VERSION "0.5"

NS_ :

BS_:

BU_: CM5 LEG_L1 LEG_L2 LEG_L3 LEG_R1 LEG_R2 LEG_R3 POWER

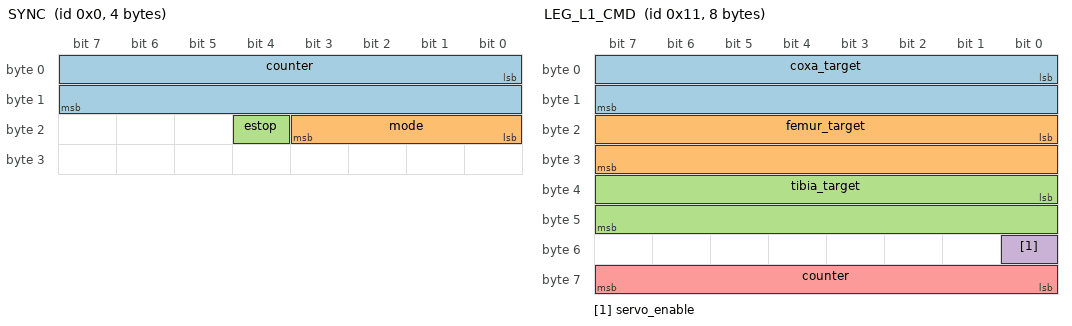
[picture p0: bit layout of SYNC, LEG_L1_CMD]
BO_ 0 SYNC: 4 CM5
 SG_ counter : 0|16@1+ (1,0) [0|65535] "" LEG_L1,LEG_L2,LEG_L3,LEG_R1,LEG_R2,LEG_R3,POWER
 SG_ mode : 16|4@1+ (1,0) [0|15] "" LEG_L1,LEG_L2,LEG_L3,LEG_R1,LEG_R2,LEG_R3,POWER
 SG_ estop : 20|1@1+ (1,0) [0|1] "" LEG_L1,LEG_L2,LEG_L3,LEG_R1,LEG_R2,LEG_R3,POWER

BO_ 17 LEG_L1_CMD: 8 CM5
 SG_ coxa_target : 0|16@1- (0.01,0) [-180|180] "deg" LEG_L1
 SG_ femur_target : 16|16@1- (0.01,0) [-180|180] "deg" LEG_L1
 SG_ tibia_target : 32|16@1- (0.01,0) [-180|180] "deg" LEG_L1
 SG_ servo_enable : 48|1@1+ (1,0) [0|1] "" LEG_L1
 SG_ counter : 56|8@1+ (1,0) [0|255] "" LEG_L1

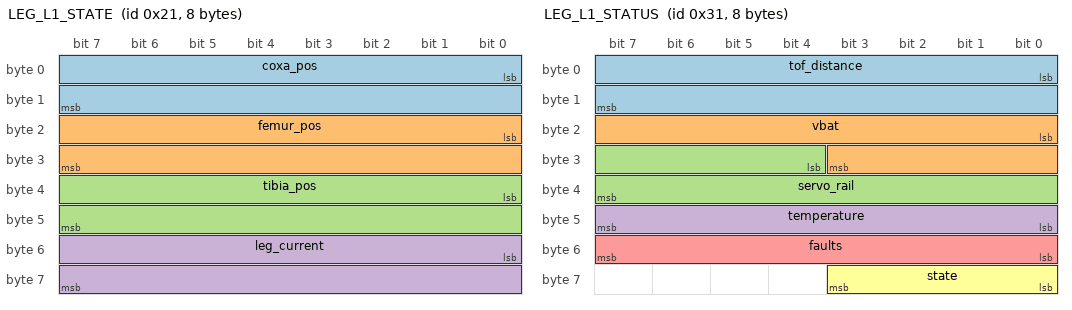
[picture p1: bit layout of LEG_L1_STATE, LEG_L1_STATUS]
BO_ 33 LEG_L1_STATE: 8 LEG_L1
 SG_ coxa_pos : 0|16@1- (0.01,0) [-180|180] "deg" CM5
 SG_ femur_pos : 16|16@1- (0.01,0) [-180|180] "deg" CM5
 SG_ tibia_pos : 32|16@1- (0.01,0) [-180|180] "deg" CM5
 SG_ leg_current : 48|16@1+ (1,0) [0|65535] "mA" CM5

BO_ 49 LEG_L1_STATUS: 8 LEG_L1
 SG_ tof_distance : 0|16@1+ (1,0) [0|65535] "mm" CM5
 SG_ vbat : 16|12@1+ (10,0) [0|40950] "mV" CM5
 SG_ servo_rail : 28|12@1+ (10,0) [0|40950] "mV" CM5
 SG_ temperature : 40|8@1- (1,0) [-128|127] "degC" CM5
 SG_ faults : 48|8@1+ (1,0) [0|255] "" CM5
 SG_ state : 56|4@1+ (1,0) [0|15] "" CM5

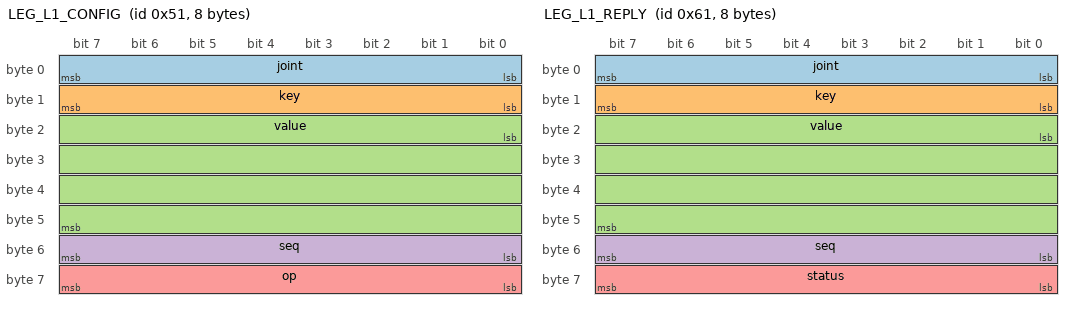
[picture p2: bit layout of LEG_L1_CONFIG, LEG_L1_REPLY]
BO_ 81 LEG_L1_CONFIG: 8 CM5
 SG_ joint : 0|8@1+ (1,0) [0|255] "" LEG_L1
 SG_ key : 8|8@1+ (1,0) [0|255] "" LEG_L1
 SG_ value : 16|32@1- (1,0) [-2147483648|2147483647] "" LEG_L1
 SG_ seq : 48|8@1+ (1,0) [0|255] "" LEG_L1
 SG_ op : 56|8@1+ (1,0) [0|255] "" LEG_L1

BO_ 97 LEG_L1_REPLY: 8 LEG_L1
 SG_ joint : 0|8@1+ (1,0) [0|255] "" CM5
 SG_ key : 8|8@1+ (1,0) [0|255] "" CM5
 SG_ value : 16|32@1- (1,0) [-2147483648|2147483647] "" CM5
 SG_ seq : 48|8@1+ (1,0) [0|255] "" CM5
 SG_ status : 56|8@1+ (1,0) [0|255] "" CM5

BO_ 113 BOOT_L1: 8 CM5
 SG_ op : 0|8@1+ (1,0) [0|255] "" LEG_L1
 SG_ payload : 8|56@1+ (1,0) [0|0] "" LEG_L1

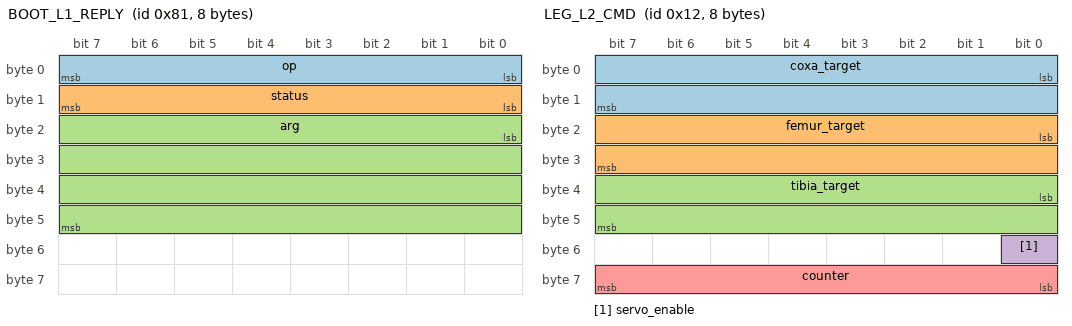
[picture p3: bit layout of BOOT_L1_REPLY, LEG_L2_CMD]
BO_ 129 BOOT_L1_REPLY: 8 LEG_L1
 SG_ op : 0|8@1+ (1,0) [0|255] "" CM5
 SG_ status : 8|8@1+ (1,0) [0|255] "" CM5
 SG_ arg : 16|32@1+ (1,0) [0|4294967295] "" CM5

BO_ 18 LEG_L2_CMD: 8 CM5
 SG_ coxa_target : 0|16@1- (0.01,0) [-180|180] "deg" LEG_L2
 SG_ femur_target : 16|16@1- (0.01,0) [-180|180] "deg" LEG_L2
 SG_ tibia_target : 32|16@1- (0.01,0) [-180|180] "deg" LEG_L2
 SG_ servo_enable : 48|1@1+ (1,0) [0|1] "" LEG_L2
 SG_ counter : 56|8@1+ (1,0) [0|255] "" LEG_L2

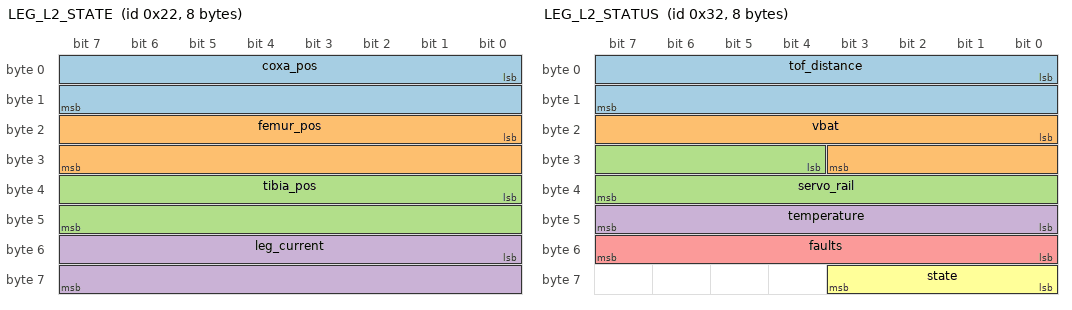
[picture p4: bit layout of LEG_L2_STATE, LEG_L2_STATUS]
BO_ 34 LEG_L2_STATE: 8 LEG_L2
 SG_ coxa_pos : 0|16@1- (0.01,0) [-180|180] "deg" CM5
 SG_ femur_pos : 16|16@1- (0.01,0) [-180|180] "deg" CM5
 SG_ tibia_pos : 32|16@1- (0.01,0) [-180|180] "deg" CM5
 SG_ leg_current : 48|16@1+ (1,0) [0|65535] "mA" CM5

BO_ 50 LEG_L2_STATUS: 8 LEG_L2
 SG_ tof_distance : 0|16@1+ (1,0) [0|65535] "mm" CM5
 SG_ vbat : 16|12@1+ (10,0) [0|40950] "mV" CM5
 SG_ servo_rail : 28|12@1+ (10,0) [0|40950] "mV" CM5
 SG_ temperature : 40|8@1- (1,0) [-128|127] "degC" CM5
 SG_ faults : 48|8@1+ (1,0) [0|255] "" CM5
 SG_ state : 56|4@1+ (1,0) [0|15] "" CM5

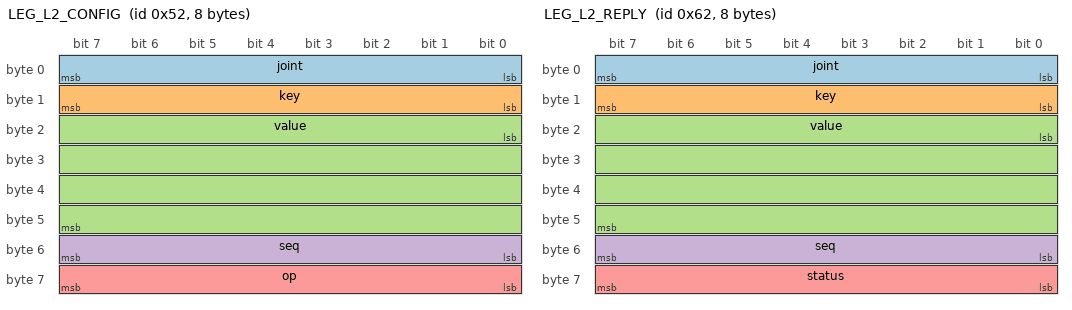
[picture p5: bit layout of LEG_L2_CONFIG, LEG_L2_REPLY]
BO_ 82 LEG_L2_CONFIG: 8 CM5
 SG_ joint : 0|8@1+ (1,0) [0|255] "" LEG_L2
 SG_ key : 8|8@1+ (1,0) [0|255] "" LEG_L2
 SG_ value : 16|32@1- (1,0) [-2147483648|2147483647] "" LEG_L2
 SG_ seq : 48|8@1+ (1,0) [0|255] "" LEG_L2
 SG_ op : 56|8@1+ (1,0) [0|255] "" LEG_L2

BO_ 98 LEG_L2_REPLY: 8 LEG_L2
 SG_ joint : 0|8@1+ (1,0) [0|255] "" CM5
 SG_ key : 8|8@1+ (1,0) [0|255] "" CM5
 SG_ value : 16|32@1- (1,0) [-2147483648|2147483647] "" CM5
 SG_ seq : 48|8@1+ (1,0) [0|255] "" CM5
 SG_ status : 56|8@1+ (1,0) [0|255] "" CM5

BO_ 114 BOOT_L2: 8 CM5
 SG_ op : 0|8@1+ (1,0) [0|255] "" LEG_L2
 SG_ payload : 8|56@1+ (1,0) [0|0] "" LEG_L2

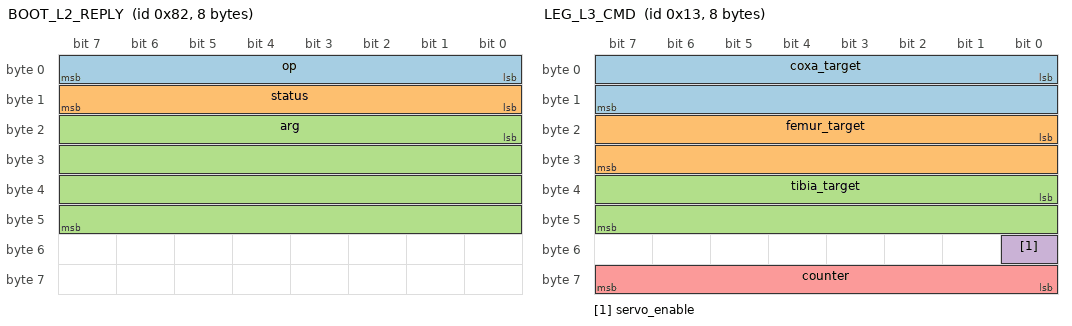
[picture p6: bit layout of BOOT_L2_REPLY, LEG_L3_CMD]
BO_ 130 BOOT_L2_REPLY: 8 LEG_L2
 SG_ op : 0|8@1+ (1,0) [0|255] "" CM5
 SG_ status : 8|8@1+ (1,0) [0|255] "" CM5
 SG_ arg : 16|32@1+ (1,0) [0|4294967295] "" CM5

BO_ 19 LEG_L3_CMD: 8 CM5
 SG_ coxa_target : 0|16@1- (0.01,0) [-180|180] "deg" LEG_L3
 SG_ femur_target : 16|16@1- (0.01,0) [-180|180] "deg" LEG_L3
 SG_ tibia_target : 32|16@1- (0.01,0) [-180|180] "deg" LEG_L3
 SG_ servo_enable : 48|1@1+ (1,0) [0|1] "" LEG_L3
 SG_ counter : 56|8@1+ (1,0) [0|255] "" LEG_L3

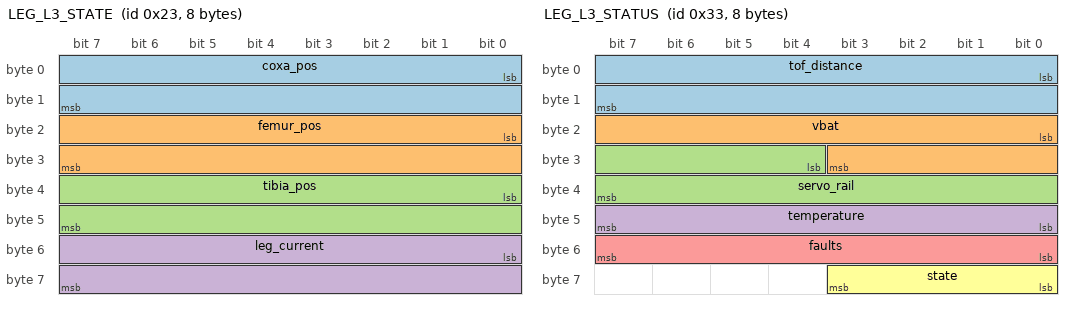
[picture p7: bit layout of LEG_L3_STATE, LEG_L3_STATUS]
BO_ 35 LEG_L3_STATE: 8 LEG_L3
 SG_ coxa_pos : 0|16@1- (0.01,0) [-180|180] "deg" CM5
 SG_ femur_pos : 16|16@1- (0.01,0) [-180|180] "deg" CM5
 SG_ tibia_pos : 32|16@1- (0.01,0) [-180|180] "deg" CM5
 SG_ leg_current : 48|16@1+ (1,0) [0|65535] "mA" CM5

BO_ 51 LEG_L3_STATUS: 8 LEG_L3
 SG_ tof_distance : 0|16@1+ (1,0) [0|65535] "mm" CM5
 SG_ vbat : 16|12@1+ (10,0) [0|40950] "mV" CM5
 SG_ servo_rail : 28|12@1+ (10,0) [0|40950] "mV" CM5
 SG_ temperature : 40|8@1- (1,0) [-128|127] "degC" CM5
 SG_ faults : 48|8@1+ (1,0) [0|255] "" CM5
 SG_ state : 56|4@1+ (1,0) [0|15] "" CM5

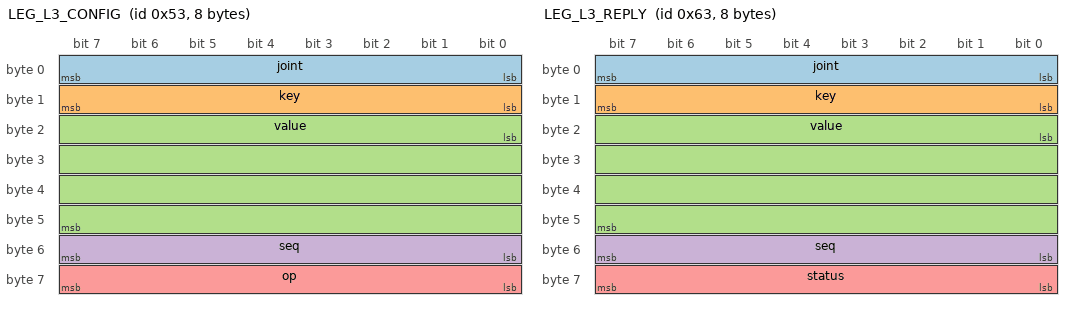
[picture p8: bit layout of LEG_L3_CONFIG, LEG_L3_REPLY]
BO_ 83 LEG_L3_CONFIG: 8 CM5
 SG_ joint : 0|8@1+ (1,0) [0|255] "" LEG_L3
 SG_ key : 8|8@1+ (1,0) [0|255] "" LEG_L3
 SG_ value : 16|32@1- (1,0) [-2147483648|2147483647] "" LEG_L3
 SG_ seq : 48|8@1+ (1,0) [0|255] "" LEG_L3
 SG_ op : 56|8@1+ (1,0) [0|255] "" LEG_L3

BO_ 99 LEG_L3_REPLY: 8 LEG_L3
 SG_ joint : 0|8@1+ (1,0) [0|255] "" CM5
 SG_ key : 8|8@1+ (1,0) [0|255] "" CM5
 SG_ value : 16|32@1- (1,0) [-2147483648|2147483647] "" CM5
 SG_ seq : 48|8@1+ (1,0) [0|255] "" CM5
 SG_ status : 56|8@1+ (1,0) [0|255] "" CM5

BO_ 115 BOOT_L3: 8 CM5
 SG_ op : 0|8@1+ (1,0) [0|255] "" LEG_L3
 SG_ payload : 8|56@1+ (1,0) [0|0] "" LEG_L3

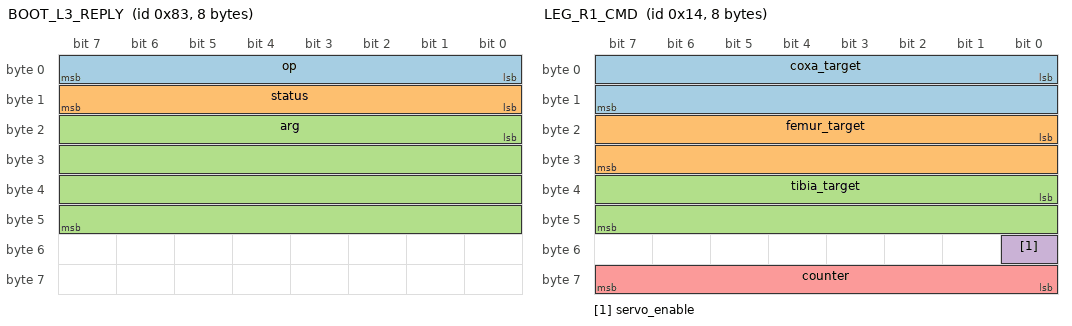
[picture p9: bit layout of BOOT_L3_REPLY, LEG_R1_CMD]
BO_ 131 BOOT_L3_REPLY: 8 LEG_L3
 SG_ op : 0|8@1+ (1,0) [0|255] "" CM5
 SG_ status : 8|8@1+ (1,0) [0|255] "" CM5
 SG_ arg : 16|32@1+ (1,0) [0|4294967295] "" CM5

BO_ 20 LEG_R1_CMD: 8 CM5
 SG_ coxa_target : 0|16@1- (0.01,0) [-180|180] "deg" LEG_R1
 SG_ femur_target : 16|16@1- (0.01,0) [-180|180] "deg" LEG_R1
 SG_ tibia_target : 32|16@1- (0.01,0) [-180|180] "deg" LEG_R1
 SG_ servo_enable : 48|1@1+ (1,0) [0|1] "" LEG_R1
 SG_ counter : 56|8@1+ (1,0) [0|255] "" LEG_R1

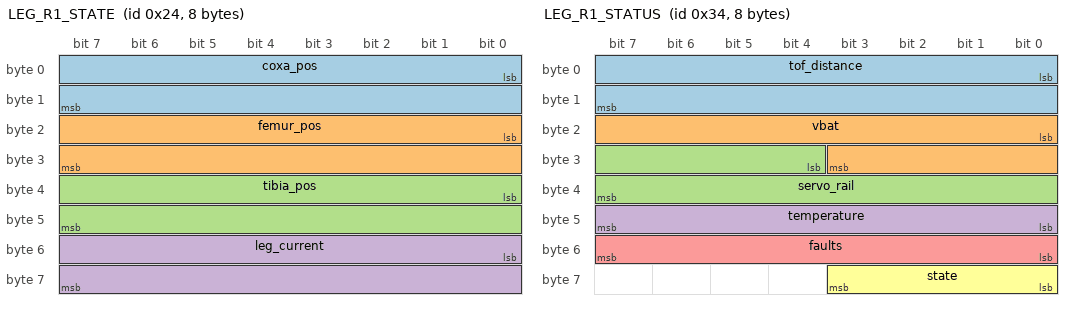
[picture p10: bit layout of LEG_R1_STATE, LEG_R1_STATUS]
BO_ 36 LEG_R1_STATE: 8 LEG_R1
 SG_ coxa_pos : 0|16@1- (0.01,0) [-180|180] "deg" CM5
 SG_ femur_pos : 16|16@1- (0.01,0) [-180|180] "deg" CM5
 SG_ tibia_pos : 32|16@1- (0.01,0) [-180|180] "deg" CM5
 SG_ leg_current : 48|16@1+ (1,0) [0|65535] "mA" CM5

BO_ 52 LEG_R1_STATUS: 8 LEG_R1
 SG_ tof_distance : 0|16@1+ (1,0) [0|65535] "mm" CM5
 SG_ vbat : 16|12@1+ (10,0) [0|40950] "mV" CM5
 SG_ servo_rail : 28|12@1+ (10,0) [0|40950] "mV" CM5
 SG_ temperature : 40|8@1- (1,0) [-128|127] "degC" CM5
 SG_ faults : 48|8@1+ (1,0) [0|255] "" CM5
 SG_ state : 56|4@1+ (1,0) [0|15] "" CM5

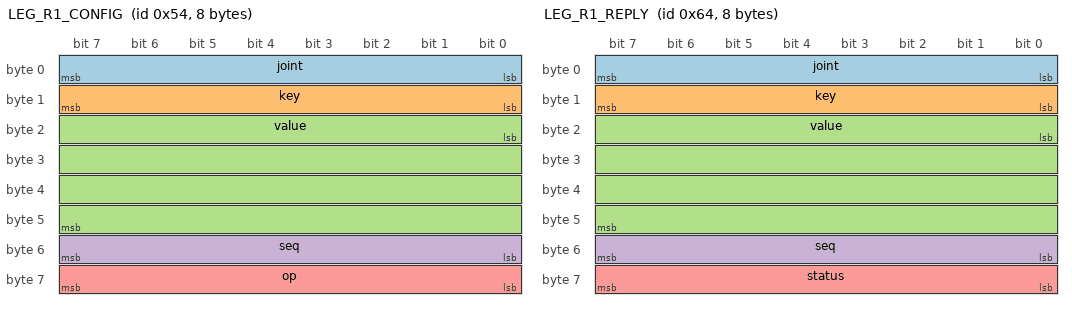
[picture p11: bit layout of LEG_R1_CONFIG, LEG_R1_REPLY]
BO_ 84 LEG_R1_CONFIG: 8 CM5
 SG_ joint : 0|8@1+ (1,0) [0|255] "" LEG_R1
 SG_ key : 8|8@1+ (1,0) [0|255] "" LEG_R1
 SG_ value : 16|32@1- (1,0) [-2147483648|2147483647] "" LEG_R1
 SG_ seq : 48|8@1+ (1,0) [0|255] "" LEG_R1
 SG_ op : 56|8@1+ (1,0) [0|255] "" LEG_R1

BO_ 100 LEG_R1_REPLY: 8 LEG_R1
 SG_ joint : 0|8@1+ (1,0) [0|255] "" CM5
 SG_ key : 8|8@1+ (1,0) [0|255] "" CM5
 SG_ value : 16|32@1- (1,0) [-2147483648|2147483647] "" CM5
 SG_ seq : 48|8@1+ (1,0) [0|255] "" CM5
 SG_ status : 56|8@1+ (1,0) [0|255] "" CM5

BO_ 116 BOOT_R1: 8 CM5
 SG_ op : 0|8@1+ (1,0) [0|255] "" LEG_R1
 SG_ payload : 8|56@1+ (1,0) [0|0] "" LEG_R1

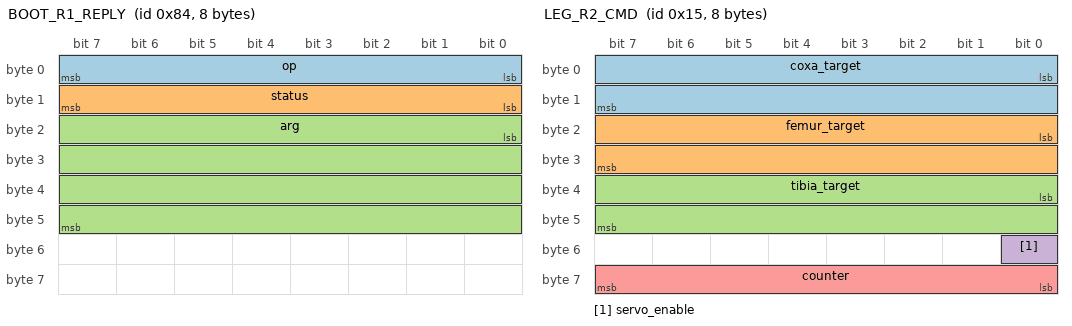
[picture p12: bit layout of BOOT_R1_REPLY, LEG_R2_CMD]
BO_ 132 BOOT_R1_REPLY: 8 LEG_R1
 SG_ op : 0|8@1+ (1,0) [0|255] "" CM5
 SG_ status : 8|8@1+ (1,0) [0|255] "" CM5
 SG_ arg : 16|32@1+ (1,0) [0|4294967295] "" CM5

BO_ 21 LEG_R2_CMD: 8 CM5
 SG_ coxa_target : 0|16@1- (0.01,0) [-180|180] "deg" LEG_R2
 SG_ femur_target : 16|16@1- (0.01,0) [-180|180] "deg" LEG_R2
 SG_ tibia_target : 32|16@1- (0.01,0) [-180|180] "deg" LEG_R2
 SG_ servo_enable : 48|1@1+ (1,0) [0|1] "" LEG_R2
 SG_ counter : 56|8@1+ (1,0) [0|255] "" LEG_R2

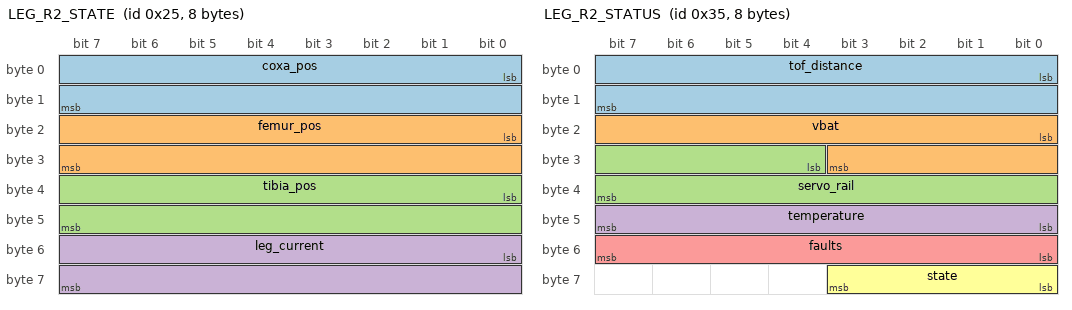
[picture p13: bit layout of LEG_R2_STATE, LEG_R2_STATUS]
BO_ 37 LEG_R2_STATE: 8 LEG_R2
 SG_ coxa_pos : 0|16@1- (0.01,0) [-180|180] "deg" CM5
 SG_ femur_pos : 16|16@1- (0.01,0) [-180|180] "deg" CM5
 SG_ tibia_pos : 32|16@1- (0.01,0) [-180|180] "deg" CM5
 SG_ leg_current : 48|16@1+ (1,0) [0|65535] "mA" CM5

BO_ 53 LEG_R2_STATUS: 8 LEG_R2
 SG_ tof_distance : 0|16@1+ (1,0) [0|65535] "mm" CM5
 SG_ vbat : 16|12@1+ (10,0) [0|40950] "mV" CM5
 SG_ servo_rail : 28|12@1+ (10,0) [0|40950] "mV" CM5
 SG_ temperature : 40|8@1- (1,0) [-128|127] "degC" CM5
 SG_ faults : 48|8@1+ (1,0) [0|255] "" CM5
 SG_ state : 56|4@1+ (1,0) [0|15] "" CM5

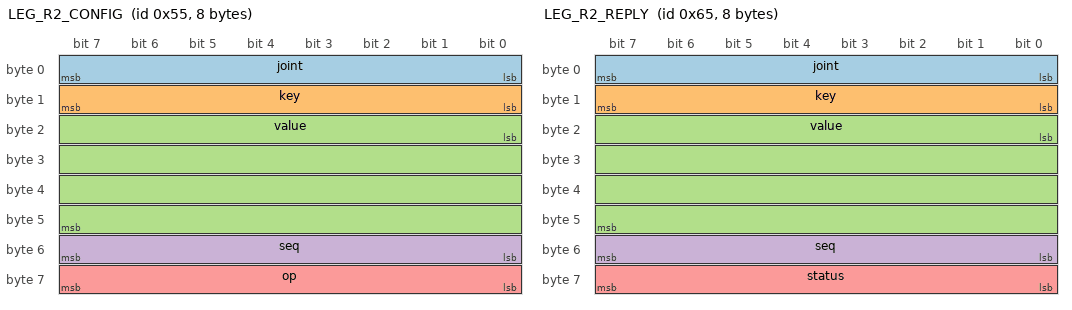
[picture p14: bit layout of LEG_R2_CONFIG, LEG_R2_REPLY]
BO_ 85 LEG_R2_CONFIG: 8 CM5
 SG_ joint : 0|8@1+ (1,0) [0|255] "" LEG_R2
 SG_ key : 8|8@1+ (1,0) [0|255] "" LEG_R2
 SG_ value : 16|32@1- (1,0) [-2147483648|2147483647] "" LEG_R2
 SG_ seq : 48|8@1+ (1,0) [0|255] "" LEG_R2
 SG_ op : 56|8@1+ (1,0) [0|255] "" LEG_R2

BO_ 101 LEG_R2_REPLY: 8 LEG_R2
 SG_ joint : 0|8@1+ (1,0) [0|255] "" CM5
 SG_ key : 8|8@1+ (1,0) [0|255] "" CM5
 SG_ value : 16|32@1- (1,0) [-2147483648|2147483647] "" CM5
 SG_ seq : 48|8@1+ (1,0) [0|255] "" CM5
 SG_ status : 56|8@1+ (1,0) [0|255] "" CM5

BO_ 117 BOOT_R2: 8 CM5
 SG_ op : 0|8@1+ (1,0) [0|255] "" LEG_R2
 SG_ payload : 8|56@1+ (1,0) [0|0] "" LEG_R2

BO_ 133 BOOT_R2_REPLY: 8 LEG_R2
 SG_ op : 0|8@1+ (1,0) [0|255] "" CM5
 SG_ status : 8|8@1+ (1,0) [0|255] "" CM5
 SG_ arg : 16|32@1+ (1,0) [0|4294967295] "" CM5

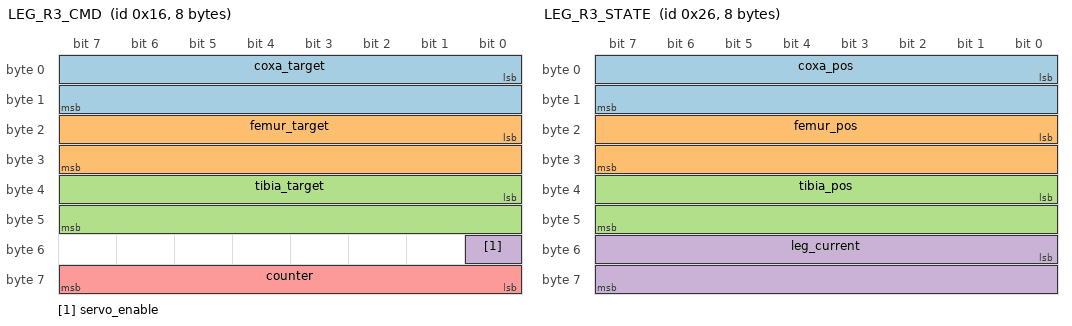
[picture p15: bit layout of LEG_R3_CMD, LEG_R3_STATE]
BO_ 22 LEG_R3_CMD: 8 CM5
 SG_ coxa_target : 0|16@1- (0.01,0) [-180|180] "deg" LEG_R3
 SG_ femur_target : 16|16@1- (0.01,0) [-180|180] "deg" LEG_R3
 SG_ tibia_target : 32|16@1- (0.01,0) [-180|180] "deg" LEG_R3
 SG_ servo_enable : 48|1@1+ (1,0) [0|1] "" LEG_R3
 SG_ counter : 56|8@1+ (1,0) [0|255] "" LEG_R3

BO_ 38 LEG_R3_STATE: 8 LEG_R3
 SG_ coxa_pos : 0|16@1- (0.01,0) [-180|180] "deg" CM5
 SG_ femur_pos : 16|16@1- (0.01,0) [-180|180] "deg" CM5
 SG_ tibia_pos : 32|16@1- (0.01,0) [-180|180] "deg" CM5
 SG_ leg_current : 48|16@1+ (1,0) [0|65535] "mA" CM5

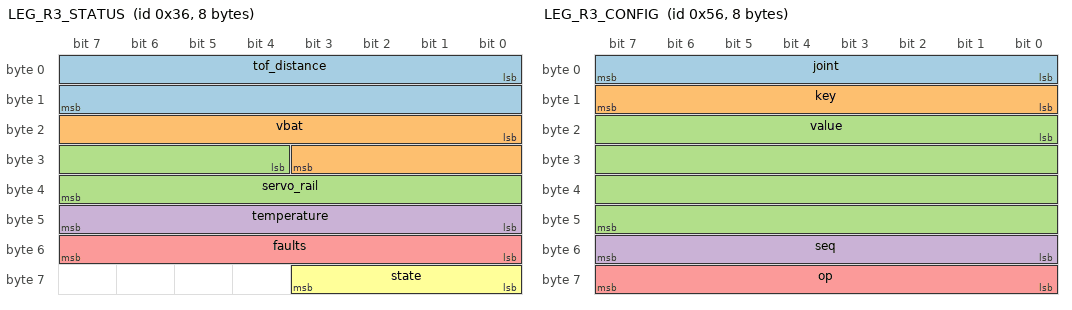
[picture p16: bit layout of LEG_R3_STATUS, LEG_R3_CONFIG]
BO_ 54 LEG_R3_STATUS: 8 LEG_R3
 SG_ tof_distance : 0|16@1+ (1,0) [0|65535] "mm" CM5
 SG_ vbat : 16|12@1+ (10,0) [0|40950] "mV" CM5
 SG_ servo_rail : 28|12@1+ (10,0) [0|40950] "mV" CM5
 SG_ temperature : 40|8@1- (1,0) [-128|127] "degC" CM5
 SG_ faults : 48|8@1+ (1,0) [0|255] "" CM5
 SG_ state : 56|4@1+ (1,0) [0|15] "" CM5

BO_ 86 LEG_R3_CONFIG: 8 CM5
 SG_ joint : 0|8@1+ (1,0) [0|255] "" LEG_R3
 SG_ key : 8|8@1+ (1,0) [0|255] "" LEG_R3
 SG_ value : 16|32@1- (1,0) [-2147483648|2147483647] "" LEG_R3
 SG_ seq : 48|8@1+ (1,0) [0|255] "" LEG_R3
 SG_ op : 56|8@1+ (1,0) [0|255] "" LEG_R3

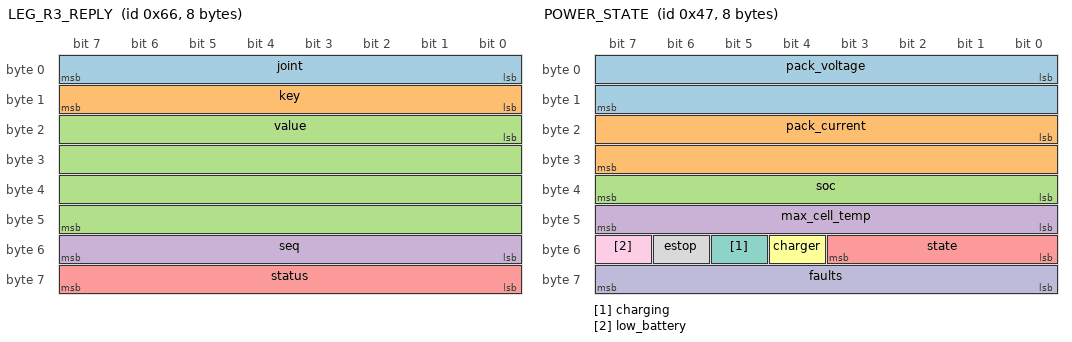
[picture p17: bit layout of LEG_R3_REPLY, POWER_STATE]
BO_ 102 LEG_R3_REPLY: 8 LEG_R3
 SG_ joint : 0|8@1+ (1,0) [0|255] "" CM5
 SG_ key : 8|8@1+ (1,0) [0|255] "" CM5
 SG_ value : 16|32@1- (1,0) [-2147483648|2147483647] "" CM5
 SG_ seq : 48|8@1+ (1,0) [0|255] "" CM5
 SG_ status : 56|8@1+ (1,0) [0|255] "" CM5

BO_ 118 BOOT_R3: 8 CM5
 SG_ op : 0|8@1+ (1,0) [0|255] "" LEG_R3
 SG_ payload : 8|56@1+ (1,0) [0|0] "" LEG_R3

BO_ 134 BOOT_R3_REPLY: 8 LEG_R3
 SG_ op : 0|8@1+ (1,0) [0|255] "" CM5
 SG_ status : 8|8@1+ (1,0) [0|255] "" CM5
 SG_ arg : 16|32@1+ (1,0) [0|4294967295] "" CM5

BO_ 71 POWER_STATE: 8 POWER
 SG_ pack_voltage : 0|16@1+ (1,0) [0|65535] "mV" CM5
 SG_ pack_current : 16|16@1- (10,0) [-327680|327670] "mA" CM5
 SG_ soc : 32|8@1+ (0.5,0) [0|100] "%" CM5
 SG_ max_cell_temp : 40|8@1- (1,0) [-128|127] "degC" CM5
 SG_ state : 48|4@1+ (1,0) [0|15] "" CM5
 SG_ charger : 52|1@1+ (1,0) [0|1] "" CM5
 SG_ charging : 53|1@1+ (1,0) [0|1] "" CM5
 SG_ estop : 54|1@1+ (1,0) [0|1] "" CM5
 SG_ low_battery : 55|1@1+ (1,0) [0|1] "" CM5
 SG_ faults : 56|8@1+ (1,0) [0|255] "" CM5

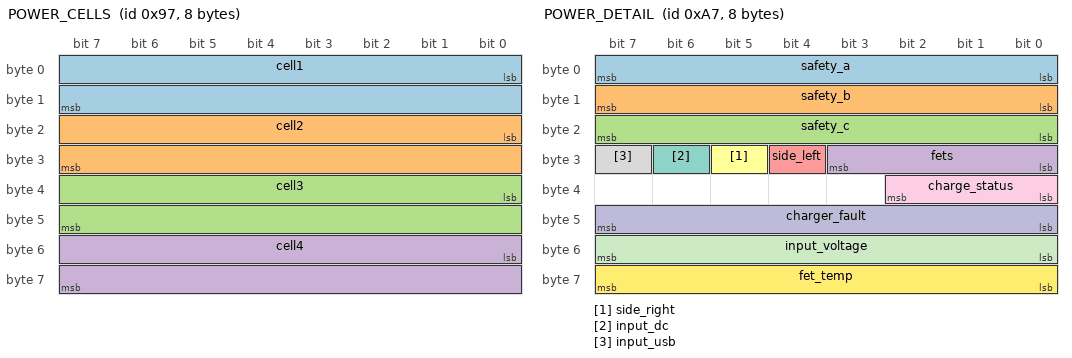
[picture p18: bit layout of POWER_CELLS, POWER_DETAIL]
BO_ 151 POWER_CELLS: 8 POWER
 SG_ cell1 : 0|16@1+ (1,0) [0|65535] "mV" CM5
 SG_ cell2 : 16|16@1+ (1,0) [0|65535] "mV" CM5
 SG_ cell3 : 32|16@1+ (1,0) [0|65535] "mV" CM5
 SG_ cell4 : 48|16@1+ (1,0) [0|65535] "mV" CM5

BO_ 167 POWER_DETAIL: 8 POWER
 SG_ safety_a : 0|8@1+ (1,0) [0|255] "" CM5
 SG_ safety_b : 8|8@1+ (1,0) [0|255] "" CM5
 SG_ safety_c : 16|8@1+ (1,0) [0|255] "" CM5
 SG_ fets : 24|4@1+ (1,0) [0|15] "" CM5
 SG_ side_left : 28|1@1+ (1,0) [0|1] "" CM5
 SG_ side_right : 29|1@1+ (1,0) [0|1] "" CM5
 SG_ input_dc : 30|1@1+ (1,0) [0|1] "" CM5
 SG_ input_usb : 31|1@1+ (1,0) [0|1] "" CM5
 SG_ charge_status : 32|3@1+ (1,0) [0|7] "" CM5
 SG_ charger_fault : 40|8@1+ (1,0) [0|255] "" CM5
 SG_ input_voltage : 48|8@1+ (100,0) [0|25500] "mV" CM5
 SG_ fet_temp : 56|8@1- (1,0) [-128|127] "degC" CM5

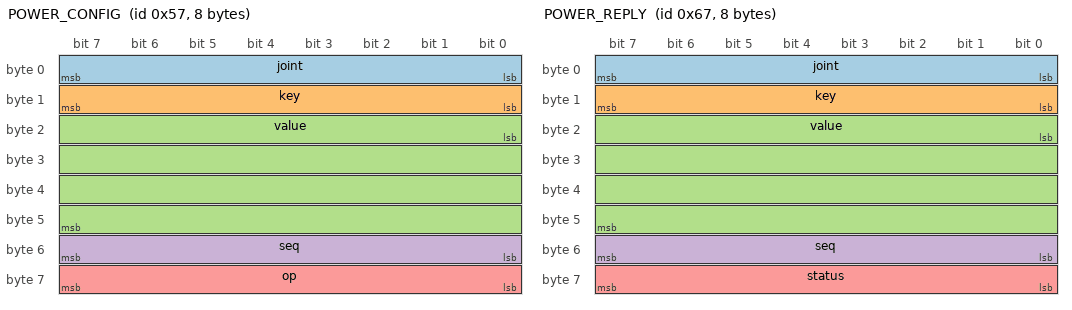
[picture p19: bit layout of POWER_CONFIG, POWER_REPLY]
BO_ 87 POWER_CONFIG: 8 CM5
 SG_ joint : 0|8@1+ (1,0) [0|255] "" POWER
 SG_ key : 8|8@1+ (1,0) [0|255] "" POWER
 SG_ value : 16|32@1- (1,0) [-2147483648|2147483647] "" POWER
 SG_ seq : 48|8@1+ (1,0) [0|255] "" POWER
 SG_ op : 56|8@1+ (1,0) [0|255] "" POWER

BO_ 103 POWER_REPLY: 8 POWER
 SG_ joint : 0|8@1+ (1,0) [0|255] "" CM5
 SG_ key : 8|8@1+ (1,0) [0|255] "" CM5
 SG_ value : 16|32@1- (1,0) [-2147483648|2147483647] "" CM5
 SG_ seq : 48|8@1+ (1,0) [0|255] "" CM5
 SG_ status : 56|8@1+ (1,0) [0|255] "" CM5

BO_ 119 BOOT_POWER: 8 CM5
 SG_ op : 0|8@1+ (1,0) [0|255] "" POWER
 SG_ payload : 8|56@1+ (1,0) [0|0] "" POWER

BO_ 135 BOOT_POWER_REPLY: 8 POWER
 SG_ op : 0|8@1+ (1,0) [0|255] "" CM5
 SG_ status : 8|8@1+ (1,0) [0|255] "" CM5
 SG_ arg : 16|32@1+ (1,0) [0|4294967295] "" CM5

CM_ "V.E.C.T.O.R. leg bus, classic CAN 1 Mbit/s. ID = (function << 4) | node.";
VAL_ 0 mode 0 "IDLE" 1 "STAND" 2 "WALK" 3 "SENTINEL" 4 "WAKE" 15 "FAULT" ;
VAL_ 49 state 0 "OFF" 1 "WAKE" 2 "ACTIVE" 3 "CROUCH" 4 "CALIBRATE" 5 "FAULT" 6 "TEST" ;
VAL_ 81 op 0 "READ" 1 "WRITE" 2 "SAVE" 3 "CALIBRATE" 4 "DEFAULTS" 5 "SELFTEST" ;
VAL_ 97 status 0 "OK" 1 "BAD_KEY" 2 "BAD_VALUE" 3 "BUSY" 4 "CAL_RESULT" 5 "CAL_FAILED" 6 "CAL_DONE" 7 "TEST_PASS" 8 "TEST_FAIL" 9 "TEST_DONE" ;
VAL_ 50 state 0 "OFF" 1 "WAKE" 2 "ACTIVE" 3 "CROUCH" 4 "CALIBRATE" 5 "FAULT" 6 "TEST" ;
VAL_ 82 op 0 "READ" 1 "WRITE" 2 "SAVE" 3 "CALIBRATE" 4 "DEFAULTS" 5 "SELFTEST" ;
VAL_ 98 status 0 "OK" 1 "BAD_KEY" 2 "BAD_VALUE" 3 "BUSY" 4 "CAL_RESULT" 5 "CAL_FAILED" 6 "CAL_DONE" 7 "TEST_PASS" 8 "TEST_FAIL" 9 "TEST_DONE" ;
VAL_ 51 state 0 "OFF" 1 "WAKE" 2 "ACTIVE" 3 "CROUCH" 4 "CALIBRATE" 5 "FAULT" 6 "TEST" ;
VAL_ 83 op 0 "READ" 1 "WRITE" 2 "SAVE" 3 "CALIBRATE" 4 "DEFAULTS" 5 "SELFTEST" ;
VAL_ 99 status 0 "OK" 1 "BAD_KEY" 2 "BAD_VALUE" 3 "BUSY" 4 "CAL_RESULT" 5 "CAL_FAILED" 6 "CAL_DONE" 7 "TEST_PASS" 8 "TEST_FAIL" 9 "TEST_DONE" ;
VAL_ 52 state 0 "OFF" 1 "WAKE" 2 "ACTIVE" 3 "CROUCH" 4 "CALIBRATE" 5 "FAULT" 6 "TEST" ;
VAL_ 84 op 0 "READ" 1 "WRITE" 2 "SAVE" 3 "CALIBRATE" 4 "DEFAULTS" 5 "SELFTEST" ;
VAL_ 100 status 0 "OK" 1 "BAD_KEY" 2 "BAD_VALUE" 3 "BUSY" 4 "CAL_RESULT" 5 "CAL_FAILED" 6 "CAL_DONE" 7 "TEST_PASS" 8 "TEST_FAIL" 9 "TEST_DONE" ;
VAL_ 53 state 0 "OFF" 1 "WAKE" 2 "ACTIVE" 3 "CROUCH" 4 "CALIBRATE" 5 "FAULT" 6 "TEST" ;
VAL_ 85 op 0 "READ" 1 "WRITE" 2 "SAVE" 3 "CALIBRATE" 4 "DEFAULTS" 5 "SELFTEST" ;
VAL_ 101 status 0 "OK" 1 "BAD_KEY" 2 "BAD_VALUE" 3 "BUSY" 4 "CAL_RESULT" 5 "CAL_FAILED" 6 "CAL_DONE" 7 "TEST_PASS" 8 "TEST_FAIL" 9 "TEST_DONE" ;
VAL_ 54 state 0 "OFF" 1 "WAKE" 2 "ACTIVE" 3 "CROUCH" 4 "CALIBRATE" 5 "FAULT" 6 "TEST" ;
VAL_ 86 op 0 "READ" 1 "WRITE" 2 "SAVE" 3 "CALIBRATE" 4 "DEFAULTS" 5 "SELFTEST" ;
VAL_ 102 status 0 "OK" 1 "BAD_KEY" 2 "BAD_VALUE" 3 "BUSY" 4 "CAL_RESULT" 5 "CAL_FAILED" 6 "CAL_DONE" 7 "TEST_PASS" 8 "TEST_FAIL" 9 "TEST_DONE" ;
VAL_ 113 op 1 "ENTER" 2 "INFO" 3 "ERASE" 4 "DATA" 5 "DONE" 6 "RUN" ;
VAL_ 129 status 0 "OK" 1 "BAD_OP" 2 "BAD_SEQ" 3 "FLASH_ERR" 4 "BAD_CRC" 5 "TOO_BIG" 6 "NO_IMAGE" 7 "BUSY" ;
VAL_ 114 op 1 "ENTER" 2 "INFO" 3 "ERASE" 4 "DATA" 5 "DONE" 6 "RUN" ;
VAL_ 130 status 0 "OK" 1 "BAD_OP" 2 "BAD_SEQ" 3 "FLASH_ERR" 4 "BAD_CRC" 5 "TOO_BIG" 6 "NO_IMAGE" 7 "BUSY" ;
VAL_ 115 op 1 "ENTER" 2 "INFO" 3 "ERASE" 4 "DATA" 5 "DONE" 6 "RUN" ;
VAL_ 131 status 0 "OK" 1 "BAD_OP" 2 "BAD_SEQ" 3 "FLASH_ERR" 4 "BAD_CRC" 5 "TOO_BIG" 6 "NO_IMAGE" 7 "BUSY" ;
VAL_ 116 op 1 "ENTER" 2 "INFO" 3 "ERASE" 4 "DATA" 5 "DONE" 6 "RUN" ;
VAL_ 132 status 0 "OK" 1 "BAD_OP" 2 "BAD_SEQ" 3 "FLASH_ERR" 4 "BAD_CRC" 5 "TOO_BIG" 6 "NO_IMAGE" 7 "BUSY" ;
VAL_ 117 op 1 "ENTER" 2 "INFO" 3 "ERASE" 4 "DATA" 5 "DONE" 6 "RUN" ;
VAL_ 133 status 0 "OK" 1 "BAD_OP" 2 "BAD_SEQ" 3 "FLASH_ERR" 4 "BAD_CRC" 5 "TOO_BIG" 6 "NO_IMAGE" 7 "BUSY" ;
VAL_ 118 op 1 "ENTER" 2 "INFO" 3 "ERASE" 4 "DATA" 5 "DONE" 6 "RUN" ;
VAL_ 134 status 0 "OK" 1 "BAD_OP" 2 "BAD_SEQ" 3 "FLASH_ERR" 4 "BAD_CRC" 5 "TOO_BIG" 6 "NO_IMAGE" 7 "BUSY" ;
VAL_ 71 state 0 "BOOT" 1 "CHARGE" 2 "ON" 3 "HALTING" 4 "OFF" 5 "FAULT" ;
VAL_ 167 charge_status 0 "NOT_CHARGING" 1 "TRICKLE" 2 "PRE" 3 "FAST" 4 "TAPER" 6 "TOPOFF" 7 "DONE" ;
VAL_ 87 op 0 "READ" 1 "WRITE" 2 "SAVE" 3 "CALIBRATE" 4 "DEFAULTS" 5 "SELFTEST" ;
VAL_ 103 status 0 "OK" 1 "BAD_KEY" 2 "BAD_VALUE" 3 "BUSY" 4 "CAL_RESULT" 5 "CAL_FAILED" 6 "CAL_DONE" 7 "TEST_PASS" 8 "TEST_FAIL" 9 "TEST_DONE" ;
VAL_ 119 op 1 "ENTER" 2 "INFO" 3 "ERASE" 4 "DATA" 5 "DONE" 6 "RUN" ;
VAL_ 135 status 0 "OK" 1 "BAD_OP" 2 "BAD_SEQ" 3 "FLASH_ERR" 4 "BAD_CRC" 5 "TOO_BIG" 6 "NO_IMAGE" 7 "BUSY" ;
